# nrf52833 register map
Vendor: Nordic Semiconductor; Series: nrf52; File version: 1
CPU: CM4 r0p1, little endian, MPU, FPU, 3 interrupt priority bits
Registers are 32-bit, read-write, reset 0x0 unless marked. A register's access mark holds for its fields unless they carry their own. Offsets are from the block's base; [hi:lo] are bit positions; lines under a group give offsets from that group; {n}, {i} and the like mark numbered series.

## FICR — Factory information configuration registers
Base 0x10000000
0x10 CODEPAGESIZE ro reset 0xFFFFFFFF — Code memory page size
0x14 CODESIZE ro reset 0xFFFFFFFF — Code memory size
  [31:0] CODESIZE — Code memory size in number of pages
{0x60+4i} DEVICEID[{i}] (i=0..1) ro reset 0xFFFFFFFF — Description collection: Device identifier
  [31:0] DEVICEID — 64 bit unique device identifier
{0x80+4i} ER[{i}] (i=0..3) ro reset 0xFFFFFFFF — Description collection: Encryption root, word n
  [31:0] ER — Encryption root, word n
{0x90+4i} IR[{i}] (i=0..3) ro reset 0xFFFFFFFF — Description collection: Identity Root, word n
  [31:0] IR — Identity Root, word n
0xA0 DEVICEADDRTYPE ro reset 0xFFFFFFFF — Device address type
  [0] DEVICEADDRTYPE
    0=Public address; 1=Random address
{0xA4+4i} DEVICEADDR[{i}] (i=0..1) ro reset 0xFFFFFFFF — Description collection: Device address n
  [31:0] DEVICEADDR — 48 bit device address
0x100 INFO group — Device info
  0x00 PART ro reset 0x52833 — Part code
    [31:0] PART
      0x52820=N52820 (nRF52820); 0x52833=N52833 (nRF52833); 0x52840=N52840 (nRF52840); 0xFFFFFFFF=Unspecified
  0x04 VARIANT ro reset 0xFFFFFFFF — Build code (hardware version and production configuration)
    [31:0] VARIANT — Build code (hardware version and production configuration). Encoded as ASCII.
      0x41414141=AAAA; 0x41414142=AAAB; 0x41414130=AAA0; 0x41414131=AAA1; 0x41414230=AAB0; 0xFFFFFFFF=Unspecified
  0x08 PACKAGE ro reset 0xFFFFFFFF — Package option
    [31:0] PACKAGE
      0x2007=QD (QDxx - 5x5 40-pin QFN); 0x2004=QI (QIxx - 7x7 73-pin aQFN); 0x2008=CJ (CJxx - 3.175 x 3.175 WLCSP); 0xFFFFFFFF=Unspecified
  0x0C RAM ro reset 0xFFFFFFFF — RAM variant
    [31:0] RAM
      16=K16 (16 kByte RAM); 32=K32 (32 kByte RAM); 64=K64 (64 kByte RAM); 128=K128 (128 kByte RAM); 0x100=K256 (256 kByte RAM); 0xFFFFFFFF=Unspecified
  0x10 FLASH ro reset 0xFFFFFFFF — Flash variant
    [31:0] FLASH
      128=K128 (128 kByte FLASH); 0x100=K256 (256 kByte FLASH); 0x200=K512 (512 kByte FLASH); 0x400=K1024 (1 MByte FLASH); 0x800=K2048 (2 MByte FLASH); 0xFFFFFFFF=Unspecified
{0x350+4i} PRODTEST[{i}] (i=0..2) ro reset 0xFFFFFFFF — Description collection: Production test signature n
  [31:0] PRODTEST — Production test signature n
    0xBB42319F=Done (Production tests done); 0xFFFFFFFF=NotDone (Production tests not done)
0x404 TEMP group — Registers storing factory TEMP module linearization coefficients
  {0x0+4j} A{j} ro reset 0xFFFFFFFF (j=0..5) — Slope definition A{j}
    [11:0] A — A (slope definition) register.
  {0x18+4j} B{j} ro reset 0xFFFFFFFF (j=0..5) — Y-intercept B{j}
    [13:0] B — B (y-intercept)
  {0x30+4j} T{j} ro reset 0xFFFFFFFF (j=0..4) — Segment end T{j}
    [7:0] T — T (segment end) register
0x450 NFC group — Unspecified
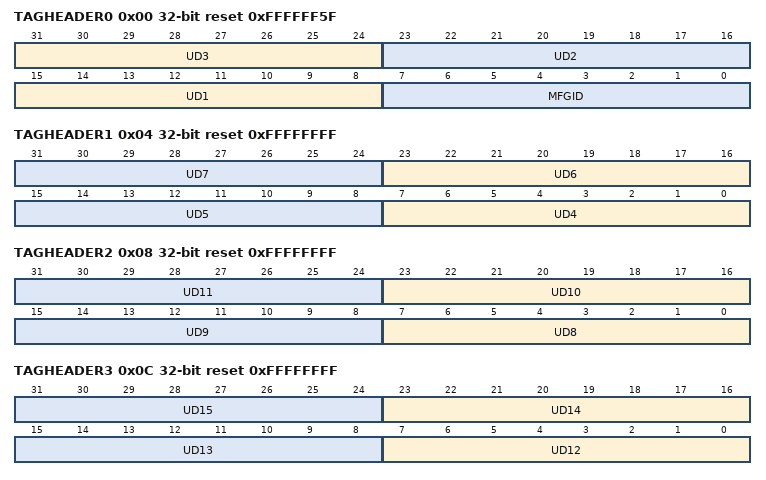
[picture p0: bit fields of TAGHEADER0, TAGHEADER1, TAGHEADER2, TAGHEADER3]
  0x00 TAGHEADER0 ro reset 0xFFFFFF5F — Default header for NFC tag. Software can read these values to populate NFCID1_3RD_LAST, NFCID1_2ND_LAST, and NFCID1_LAST.
    [31:24] UD3 — Unique identifier byte 3
    [23:16] UD2 — Unique identifier byte 2
    [15:8] UD1 — Unique identifier byte 1
    [7:0] MFGID — Default Manufacturer ID: Nordic Semiconductor ASA has ICM 0x5F
  0x04 TAGHEADER1 ro reset 0xFFFFFFFF — Default header for NFC tag. Software can read these values to populate NFCID1_3RD_LAST, NFCID1_2ND_LAST, and NFCID1_LAST.
    [8n-25:8n-32] UD{n} (n=4..7) — Unique identifier byte {n}
  0x08 TAGHEADER2 ro reset 0xFFFFFFFF — Default header for NFC tag. Software can read these values to populate NFCID1_3RD_LAST, NFCID1_2ND_LAST, and NFCID1_LAST.
    [8n-57:8n-64] UD{n} (n=8..11) — Unique identifier byte {n}
  0x0C TAGHEADER3 ro reset 0xFFFFFFFF — Default header for NFC tag. Software can read these values to populate NFCID1_3RD_LAST, NFCID1_2ND_LAST, and NFCID1_LAST.
    [8n-89:8n-96] UD{n} (n=12..15) — Unique identifier byte {n}

## Notices in the file
Copyright (c) 2010 - 2025, Nordic Semiconductor ASA All rights reserved.
SPDX-License-Identifier: BSD-3-Clause
Redistribution and use in source and binary forms, with or without
modification, are permitted provided that the following conditions are met:
1. Redistributions of source code must retain the above copyright notice, this
list of conditions and the following disclaimer.
2. Redistributions in binary form must reproduce the above copyright
notice, this list of conditions and the following disclaimer in the
documentation and/or other materials provided with the distribution.
3. Neither the name of Nordic Semiconductor ASA nor the names of its
contributors may be used to endorse or promote products derived from this
software without specific prior written permission.
THIS SOFTWARE IS PROVIDED BY THE COPYRIGHT HOLDERS AND CONTRIBUTORS "AS IS"
AND ANY EXPRESS OR IMPLIED WARRANTIES, INCLUDING, BUT NOT LIMITED TO, THE
IMPLIED WARRANTIES OF MERCHANTABILITY, AND FITNESS FOR A PARTICULAR PURPOSE
ARE DISCLAIMED. IN NO EVENT SHALL NORDIC SEMICONDUCTOR ASA OR CONTRIBUTORS BE
LIABLE FOR ANY DIRECT, INDIRECT, INCIDENTAL, SPECIAL, EXEMPLARY, OR
CONSEQUENTIAL DAMAGES (INCLUDING, BUT NOT LIMITED TO, PROCUREMENT OF
SUBSTITUTE GOODS OR SERVICES; LOSS OF USE, DATA, OR PROFITS; OR BUSINESS
INTERRUPTION) HOWEVER CAUSED AND ON ANY THEORY OF LIABILITY, WHETHER IN
CONTRACT, STRICT LIABILITY, OR TORT (INCLUDING NEGLIGENCE OR OTHERWISE)
ARISING IN ANY WAY OUT OF THE USE OF THIS SOFTWARE, EVEN IF ADVISED OF THE
POSSIBILITY OF SUCH DAMAGE.
